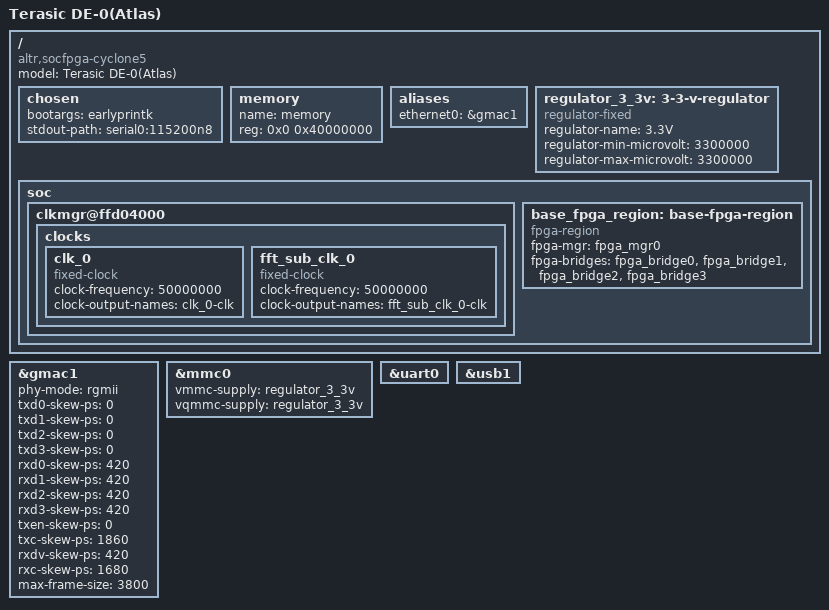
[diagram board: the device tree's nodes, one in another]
/*
 * Copyright Altera Corporation (C) 2015. All rights reserved.
 *
 * This program is free software; you can redistribute it and/or modify
 * it under the terms and conditions of the GNU General Public License,
 * version 2, as published by the Free Software Foundation.
 *
 * This program is distributed in the hope it will be useful, but WITHOUT
 * ANY WARRANTY; without even the implied warranty of MERCHANTABILITY or
 * FITNESS FOR A PARTICULAR PURPOSE.  See the GNU General Public License for
 * more details.
 *
 * You should have received a copy of the GNU General Public License along with
 * this program.  If not, see <http://www.gnu.org/licenses/>.
 */

#include "socfpga_cyclone5.dtsi"
/ {
	model = "Terasic DE-0(Atlas)";
	compatible = "altr,socfpga-cyclone5", "altr,socfpga";

	chosen {
		bootargs = "earlyprintk";
		stdout-path = "serial0:115200n8";
	};

	memory {
		name = "memory";
		device_type = "memory";
		reg = <0x0 0x40000000>; /* 1GB */
	};

	aliases {
		ethernet0 = &gmac1;
	};

	regulator_3_3v: 3-3-v-regulator {
		compatible = "regulator-fixed";
		regulator-name = "3.3V";
		regulator-min-microvolt = <3300000>;
		regulator-max-microvolt = <3300000>;
	};

	soc {
		clkmgr@ffd04000 {
			clocks {
				#clock-cells = <0>;
							   
				clk_0: clk_0 {
					#clock-cells = <0>;
					compatible = "fixed-clock";	
					clock-frequency = <50000000>;
					clock-output-names = "clk_0-clk";
				};
				
				fft_sub_clk_0: fft_sub_clk_0 {
					#clock-cells = <0>;
					compatible = "fixed-clock";
					clock-frequency = <50000000>;
					clock-output-names = "fft_sub_clk_0-clk";
				}; 
							
			};
		};
		
		base_fpga_region: base-fpga-region {
			compatible = "fpga-region";
			fpga-mgr = <&fpga_mgr0>;
			fpga-bridges = <&fpga_bridge0>, <&fpga_bridge1>,
					<&fpga_bridge2>, <&fpga_bridge3>;
	
			#address-cells = <0x2>;
			#size-cells = <0x1>;
			ranges = <0x00000000 0x00000000 0xc0000000 0x20000000>,
				<0x00000001 0x00000000 0xff200000 0x00200000>;
		};
		
	};
	
};

&gmac1 {
	status = "okay";
	phy-mode = "rgmii";

	txd0-skew-ps = <0>; /* -420ps */
	txd1-skew-ps = <0>; /* -420ps */
	txd2-skew-ps = <0>; /* -420ps */
	txd3-skew-ps = <0>; /* -420ps */
	rxd0-skew-ps = <420>; /* 0ps */
	rxd1-skew-ps = <420>; /* 0ps */
	rxd2-skew-ps = <420>; /* 0ps */
	rxd3-skew-ps = <420>; /* 0ps */
	txen-skew-ps = <0>; /* -420ps */
	txc-skew-ps = <1860>; /* 960ps */
	rxdv-skew-ps = <420>; /* 0ps */
	rxc-skew-ps = <1680>; /* 780ps */

	max-frame-size = <3800>;
};


&mmc0 {
	vmmc-supply = <&regulator_3_3v>;
	vqmmc-supply = <&regulator_3_3v>;
};

&uart0 {
	status = "okay";
};

&usb1 {
	status = "okay";
};

